# M55M1 register map
File version: 1.0
Registers are 32-bit, read-write, reset 0x0 unless marked. A register's access mark holds for its fields unless they carry their own. Offsets are from the block's base; [hi:lo] are bit positions; {n}, {i} and the like mark numbered series.

## LPUART0 — LPUART Register Map
Base 0x40446000
Same registers: LPUART0_NS 0x50446000
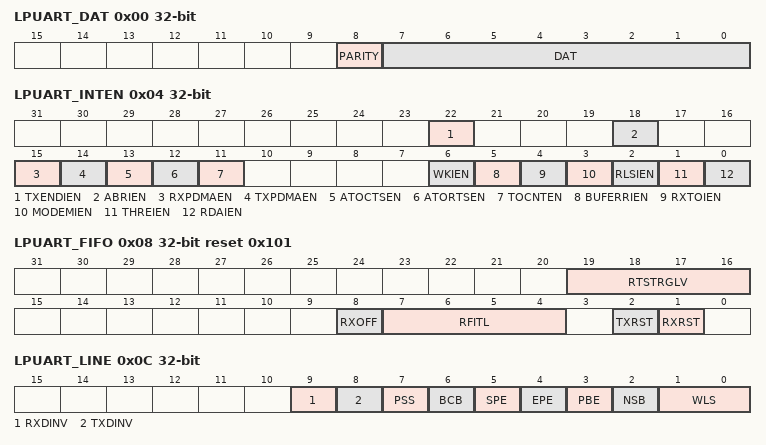
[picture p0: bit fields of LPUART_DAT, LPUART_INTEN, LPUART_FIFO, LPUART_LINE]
0x00 LPUART_DAT reset not defined — LPUART Receive/Transmit Buffer Register
  [8] PARITY — PARITY Bit Receive/Transmit Buffer. Write Operation: By writing to this bit, the PARITY bit will be stored in transmitter FIFO. If PBE (LPUART_LINE[3]) and PSS (LPUART_LINE[7]) are set, the LPUART controller will send out this bit follow the DAT (LPUART_DAT[7:0]) through the LPUART_TXD. Read Operation: If PBE (LPUART_LINE[3]) and PSS (LPUART_LINE[7]) are enabled, the PARITY bit can be read by this bit. Note: This bit has effect only when PBE (LPUART_LINE[3]) and PSS (LPUART_LINE[7]) are set.
  [7:0] DAT — Data Receive/Transmit Buffer. Write Operation: By writing one byte to this register, the data byte will be stored in transmitter FIFO. The LPUART controller will send out the data stored in transmitter FIFO top location through the LPUART_TXD. Read Operation: By reading this register, the LPUART controller will return an 8-bit data received from receiver FIFO.
0x04 LPUART_INTEN — LPUART Interrupt Enable Register
  [22] TXENDIEN — Transmitter Empty Interrupt Enable Bit. If TXENDIEN (LPUART_INTEN[22]) is enabled, the Transmitter Empty interrupt TXENDINT (LPUART_INTSTS[30]) will be generated when TXENDIF (LPUART_INTSTS[22]) is set (TX FIFO (LPUART_DAT) is empty and the STOP bit of the last byte has been transmitted).
    0=Transmitter empty interrupt Disabled; 1=Transmitter empty interrupt Enabled
  [18] ABRIEN — Auto-baud Rate Interrupt Enable Bit
    0=Auto-baud rate interrupt Disabled; 1=Auto-baud rate interrupt Enabled
  [15] RXPDMAEN — RX LPPDMA Enable Bit. This bit can enable or disable RX LPPDMA service. Note: If RLSIEN (LPUART_INTEN[2]) is enabled and HWRLSINT (LPUART_INTSTS[26]) is set to 1, the RLS (Receive Line Status) Interrupt is caused. If RLS interrupt is caused by Break Error Flag BIF(LPUART_FIFOSTS[6]), Frame Error Flag FEF(LPUART_FIFO[5]) or Parity Error Flag PEF(LPUART_FIFOSTS[4]), LPUART LPPDMA receive request operation is stopped. Clear Break Error Flag BIF or Frame Error Flag FEF or Parity Error Flag PEF by writing '1' to corresponding BIF, FEF and PEF to make LPUART LPPDMA receive request operation continue.
    0=RX LPPDMA Disabled; 1=RX LPPDMA Enabled
  [14] TXPDMAEN — TX LPPDMA Enable Bit. Note: If RLSIEN (LPUART_INTEN[2]) is enabled and HWRLSINT (LPUART_INTSTS[26]) is set to 1, the RLS (Receive Line Status) Interrupt is caused. If RLS interrupt is caused by Break Error Flag BIF(LPUART_FIFOSTS[6]), Frame Error Flag FEF(LPUART_FIFO[5]) or Parity Error Flag PEF(LPUART_FIFOSTS[4]), LPUART LPPDMA transmit request operation is stopped. Clear Break Error Flag BIF or Frame Error Flag FEF or Parity Error Flag PEF by writing '1' to corresponding BIF, FEF and PEF to make LPUART LPPDMA transmit request operation continue.
    0=TX LPPDMA Disabled; 1=TX LPPDMA Enabled
  [13] ATOCTSEN — nCTS Auto-flow Control Enable Bit. Note: When nCTS auto-flow is enabled, the LPUART will send data to external device if nCTS input assert (LPUART will not send data to device until nCTS is asserted).
    0=nCTS auto-flow control Disabled; 1=nCTS auto-flow control Enabled
  [12] ATORTSEN — nRTS Auto-flow Control Enable Bit. Note: When nRTS auto-flow is enabled, if the number of bytes in the RX FIFO equals the RTSTRGLV (LPUART_FIFO[19:16]), the LPUART will de-assert nRTS signal.
    0=nRTS auto-flow control Disabled; 1=nRTS auto-flow control Enabled
  [11] TOCNTEN — Receive Buffer Time-out Counter Enable Bit
    0=Receive Buffer Time-out counter Disabled; 1=Receive Buffer Time-out counter Enabled
  [6] WKIEN — Wake-up Interrupt Enable Bit
    0=Wake-up Interrupt Disabled; 1=Wake-up Interrupt Enabled
  [5] BUFERRIEN — Buffer Error Interrupt Enable Bit
    0=Buffer error interrupt Disabled; 1=Buffer error interrupt Enabled
  [4] RXTOIEN — RX Time-out Interrupt Enable Bit
    0=RX time-out interrupt Disabled; 1=RX time-out interrupt Enabled
  [3] MODEMIEN — Modem Status Interrupt Enable Bit
    0=Modem status interrupt Disabled; 1=Modem status interrupt Enabled
  [2] RLSIEN — Receive Line Status Interrupt Enable Bit
    0=Receive Line Status interrupt Disabled; 1=Receive Line Status interrupt Enabled
  [1] THREIEN — Transmit Holding Register Empty Interrupt Enable Bit
    0=Transmit holding register empty interrupt Disabled; 1=Transmit holding register empty interrupt Enabled
  [0] RDAIEN — Receive Data Available Interrupt Enable Bit
    0=Receive data available interrupt Disabled; 1=Receive data available interrupt Enabled
0x08 LPUART_FIFO reset 0x101 — LPUART FIFO Control Register
  [19:16] RTSTRGLV — nRTS Trigger Level for Auto-flow Control. Note: This field is used for auto nRTS flow control.
    0=nRTS Trigger Level is 1 byte; 1=nRTS Trigger Level is 4 bytes; 2=nRTS Trigger Level is 8 bytes; 3=nRTS Trigger Level is 14 bytes
  [8] RXOFF — Receiver Disable Bit. The receiver is disabled or not (set 1 to disable receiver). Note: This bit is used for RS-485 Normal Multi-drop mode. It should be programmed before RS485NMM (LPUART_ALTCTL [8]) is programmed.
    0=Receiver Enabled; 1=Receiver Disabled
  [7:4] RFITL — RX FIFO Interrupt Trigger Level. When the number of bytes in the receive FIFO equals the RFITL, the RDAIF (LPUART_INTSTS[0]) will be set (if RDAIEN (LPUART_INTEN [0]) enabled, and an interrupt will be generated).
    0=RX FIFO Interrupt Trigger Level is 1 byte; 1=RX FIFO Interrupt Trigger Level is 4 bytes; 2=RX FIFO Interrupt Trigger Level is 8 bytes; 3=RX FIFO Interrupt Trigger Level is 14 bytes
  [2] TXRST — TX Field Software Reset. When TXRST (LPUART_FIFO[2]) is set, all the byte in the transmit FIFO and TX internal state machine are cleared. Note 1: This bit will automatically clear at least 3 LPUART peripheral clock cycles. Note 2: Before setting this bit, it should wait for the TXEMPTYF (LPUART_FIFOSTS[28]) be set.
    0=No effect; 1=Reset the TX internal state machine and pointers
  [1] RXRST — RX Field Software Reset. When RXRST (LPUART_FIFO[1]) is set, all the byte in the receiver FIFO and RX internal state machine are cleared. Note 1: This bit will automatically clear at least 3 LPUART peripheral clock cycles. Note 2: Before setting this bit, it should wait for the RXIDLE (LPUART_FIFOSTS[29]) be set.
    0=No effect; 1=Reset the RX internal state machine and pointers
0x0C LPUART_LINE — LPUART Line Control Register
  [9] RXDINV — RX Data Inverted. Note 1: Before setting this bit, TXRXDIS (LPUART_FUNCSEL[3]) should be set then waited for TXRXACT (LPUART_FIFOSTS[31]) is cleared. When the configuration is done, cleared TXRXDIS (LPUART_FUNCSEL[3]) to activate LPUART controller. Note 2: This bit is valid when FUNCSEL (LPUART_FUNCSEL[2:0]) is select LPUART or RS485 function.
    0=Received data signal inverted Disabled; 1=Received data signal inverted Enabled
  [8] TXDINV — TX Data Inverted. Note 1: Before setting this bit, TXRXDIS (LPUART_FUNCSEL[3]) should be set then waited for TXRXACT (LPUART_FIFOSTS[31]) is cleared. When the configuration is done, cleared TXRXDIS (LPUART_FUNCSEL[3]) to activate LPUART controller. Note 2: This bit is valid when FUNCSEL (LPUART_FUNCSEL[2:0]) is select LPUART or RS485 function.
    0=Transmitted data signal inverted Disabled; 1=Transmitted data signal inverted Enabled
  [7] PSS — PARITY Bit Source Selection. The PARITY bit can be selected to be generated and checked automatically or by software. Note 1: This bit has effect only when PBE (LPUART_LINE[3]) is set. Note 2: If PSS is 0, the PARITY bit is transmitted and checked automatically. If PSS is 1, the transmitted PARITY bit value can be determined by writing PARITY (LPUART_DAT[8]) and the PARITY bit can be read by reading PARITY (LPUART_DAT[8]).
    0=PARITY bit is generated by EPE (LPUART_LINE[4]) and SPE (LPUART_LINE[5]) setting and checked automatically; 1=PARITY bit generated and checked by software
  [6] BCB — Break Control Bit. Note: When this bit is set to logic 1, the transmitted serial data output (TX) is forced to the Spacing State (logic 0). This bit acts only on TX line and has no effect on the transmitter logic.
    0=Break Control Disabled; 1=Break Control Enabled
  [5] SPE — Stick Parity Enable Bit. Note: If PBE (LPUART_LINE[3]) and EPE (LPUART_LINE[4]) are logic 1, the PARITY bit is transmitted and checked as logic 0. If PBE (LPUART_LINE[3]) is 1 and EPE (LPUART_LINE[4]) is 0 then the PARITY bit is transmitted and checked as 1.
    0=Stick parity Disabled; 1=Stick parity Enabled
  [4] EPE — Even Parity Enable Bit. Note: This bit has effect only when PBE (LPUART_LINE[3]) is set.
    0=Odd number of logic 1's is transmitted and checked in each word; 1=Even number of logic 1's is transmitted and checked in each word
  [3] PBE — PARITY Bit Enable Bit. Note: PARITY bit is generated on each outgoing character and is checked on each incoming data.
    0=PARITY bit generated Disabled; 1=PARITY bit generated Enabled
  [2] NSB — Number of 'STOP Bit'
    0=One 'STOP bit' is generated in the transmitted data; 1=When select 5-bit word length, 1.5 'STOP bit' is generated in the transmitted data. When select 6-, 7- and 8-bit word length, 2 'STOP bit' is generated in the transmitted data
  [1:0] WLS — Word Length Selection. This field sets LPUART word length.
    {v}={v+5} bits (v=0..3)
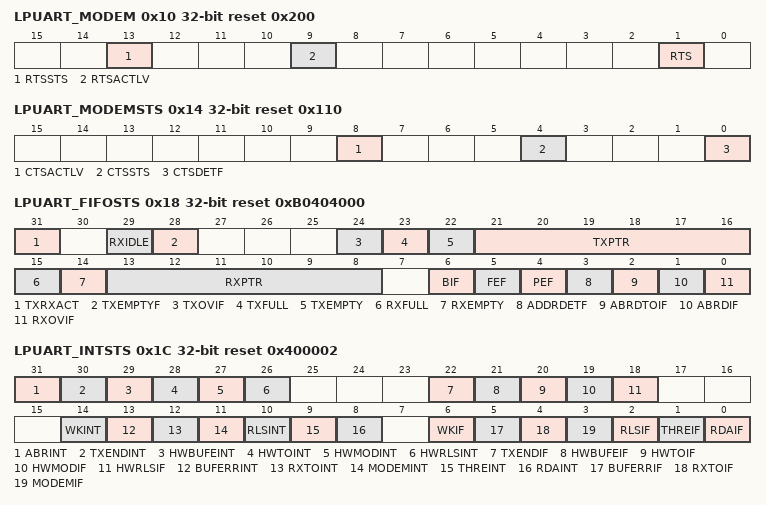
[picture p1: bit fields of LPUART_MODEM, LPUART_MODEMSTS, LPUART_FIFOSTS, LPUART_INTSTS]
0x10 LPUART_MODEM reset 0x200 — LPUART Modem Control Register
  [13] RTSSTS ro — nRTS Pin Status (Read Only). This bit mirror from nRTS pin output of voltage logic status.
    0=nRTS pin output is low level voltage logic state; 1=nRTS pin output is high level voltage logic state
  [9] RTSACTLV — nRTS Pin Active Level. This bit defines the active level state of nRTS pin output. Note 1: Refer to Figure 6.2613 and Figure 6.2614 for LPUART function mode. Note 2: Refer to Figure 6.2624 and Figure 6.2625 for RS-485 function mode. Note 3: Before setting this bit, TXRXDIS (LPUART_FUNCSEL[3]) should be set then waited for TXRXACT (LPUART_FIFOSTS[31]) is cleared. When the configuration is done, cleared TXRXDIS (LPUART_FUNCSEL[3]) to activate LPUART controller.
    0=nRTS pin output is high level active; 1=nRTS pin output is low level active. (Default)
  [1] RTS — nRTS Signal Control. This bit is direct control internal nRTS (Request-to-send) signal active or not, and then drive the nRTS pin output with RTSACTLV bit configuration. Note 1: The nRTS signal control bit is not effective when nRTS auto-flow control is enabled in LPUART function mode. Note 2: The nRTS signal control bit is not effective when RS-485 auto direction mode (AUD) is enabled in RS-485 function mode.
    0=nRTS signal is active; 1=nRTS signal is inactive
0x14 LPUART_MODEMSTS reset 0x110 — LPUART Modem Status Register
  [8] CTSACTLV — nCTS Pin Active Level. This bit defines the active level state of nCTS pin input. Note: Before setting this bit, TXRXDIS (LPUART_FUNCSEL[3]) should be set then waited for TXRXACT (LPUART_FIFOSTS[31]) is cleared. When the configuration is done, cleared TXRXDIS (LPUART_FUNCSEL[3]) to activate LPUART controller.
    0=nCTS pin input is high level active; 1=nCTS pin input is low level active. (Default)
  [4] CTSSTS ro — nCTS Pin Status (Read Only). This bit mirror from nCTS pin input of voltage logic status. Note: This bit echoes when LPUART controller peripheral clock is enabled, and nCTS multi-function port is selected.
    0=nCTS pin input is low level voltage logic state; 1=nCTS pin input is high level voltage logic state
  [0] CTSDETF — Detect nCTS State Change Flag. This bit is set whenever nCTS input has change state, and it will generate Modem interrupt to CPU when MODEMIEN (LPUART_INTEN [3]) is set to 1. Note: This bit can be cleared by writing '1' to it.
    0=nCTS input has not change state; 1=nCTS input has change state
0x18 LPUART_FIFOSTS reset 0xB0404000 — LPUART FIFO Status Register
  [31] TXRXACT ro — TX and RX Active Status (Read Only). This bit indicates TX and RX are active or inactive. Note: When TXRXDIS (LPUART_FUNCSEL[3]) is set and both TX and RX are in idle state, this bit is cleared. The LPUART controller cannot transmit or receive data at this moment. Otherwise this bit is set.
    0=TX and RX are inactive; 1=TX and RX are active. (Default)
  [29] RXIDLE ro — RX Idle Status (Read Only). This bit is set by hardware when RX is idle.
    0=RX is busy; 1=RX is idle. (Default)
  [28] TXEMPTYF ro — Transmitter Empty Flag (Read Only). This bit is set by hardware when TX FIFO (LPUART_DAT) is empty and the STOP bit of the last byte has been transmitted. Note: This bit is cleared automatically when TX FIFO is not empty or the last byte transmission has not completed.
    0=TX FIFO is not empty or the STOP bit of the last byte has been not transmitted; 1=TX FIFO is empty and the STOP bit of the last byte has been transmitted
  [24] TXOVIF — TX Overflow Error Interrupt Flag. If TX FIFO (LPUART_DAT) is full, an additional write to LPUART_DAT will cause this bit to logic 1. Note: This bit can be cleared by writing '1' to it.
    0=TX FIFO is not overflow; 1=TX FIFO is overflow
  [23] TXFULL ro — Transmitter FIFO Full (Read Only). This bit indicates TX FIFO full or not. Note: This bit is set when the number of usage in TX FIFO Buffer is equal to 16, otherwise it is cleared by hardware.
    0=TX FIFO is not full; 1=TX FIFO is full
  [22] TXEMPTY ro — Transmitter FIFO Empty (Read Only). This bit indicates TX FIFO empty or not. Note: When the last byte of TX FIFO has been transferred to Transmitter Shift Register, hardware sets this bit high. It will be cleared when writing data into LPUART_DAT (TX FIFO not empty).
    0=TX FIFO is not empty; 1=TX FIFO is empty
  [21:16] TXPTR ro — TX FIFO Pointer (Read Only). This field indicates the TX FIFO Buffer Pointer. When CPU writes one byte into LPUART_DAT, TXPTR increases one. When one byte of TX FIFO is transferred to Transmitter Shift Register, TXPTR decreases one. The Maximum value shown in TXPTR is 15. When the using level of TX FIFO Buffer equal to 16, the TXFULL bit is set to 1 and TXPTR will show 0. As one byte of TX FIFO is transferred to Transmitter Shift Register, the TXFULL bit is cleared to 0 and TXPTR will show 15.
  [15] RXFULL ro — Receiver FIFO Full (Read Only). This bit initiates RX FIFO full or not. Note: This bit is set when the number of usage in RX FIFO Buffer is equal to 16, otherwise it is cleared by hardware.
    0=RX FIFO is not full; 1=RX FIFO is full
  [14] RXEMPTY ro — Receiver FIFO Empty (Read Only). This bit initiate RX FIFO empty or not. Note: When the last byte of RX FIFO has been read by CPU, hardware sets this bit high. It will be cleared when LPUART receives any new data.
    0=RX FIFO is not empty; 1=RX FIFO is empty
  [13:8] RXPTR ro — RX FIFO Pointer (Read Only). This field indicates the RX FIFO Buffer Pointer. When LPUART receives one byte from external device, RXPTR increases one. When one byte of RX FIFO is read by CPU, RXPTR decreases one. The Maximum value shown in RXPTR is 15. When the using level of RX FIFO Buffer equal to 16, the RXFULL bit is set to 1 and RXPTR will show 0. As one byte of RX FIFO is read by CPU, the RXFULL bit is cleared to 0 and RXPTR will show 15.
  [6] BIF — Break Interrupt Flag. This bit is set to logic 1 whenever the received data input (RX) is held in the 'spacing state' (logic 0) for longer than a full word transmission time (that is, the total time of 'START bit' + data bits + parity + STOP bits). Note: This bit can be cleared by writing '1' to it.
    0=No Break interrupt is generated; 1=Break interrupt is generated
  [5] FEF — Framing Error Flag. This bit is set to logic 1 whenever the received character does not have a valid 'STOP bit' (that is, the STOP bit following the last data bit or PARITY bit is detected as logic 0). Note: This bit can be cleared by writing '1' to it.
    0=No framing error is generated; 1=Framing error is generated
  [4] PEF — Parity Error Flag. This bit is set to logic 1 whenever the received character does not have a valid 'PARITY bit'. Note: This bit can be cleared by writing '1' to it.
    0=No parity error is generated; 1=Parity error is generated
  [3] ADDRDETF — RS-485 Address Byte Detect Flag. Note 1: This field is used for RS-485 function mode and ADDRDEN (LPUART_ALTCTL[15]) is set to 1 to enable Address detection mode. Note 2: This bit can be cleared by writing '1' to it.
    0=Receiver detects a data that is not an address bit (bit 9 ='0'); 1=Receiver detects a data that is an address bit (bit 9 ='1')
  [2] ABRDTOIF — Auto-baud Rate Detect Time-out Interrupt Flag. This bit is set to logic '1' in Auto-baud Rate Detect mode when the baud rate counter is overflow. Note: This bit can be cleared by writing '1' to it.
    0=Auto-baud rate counter is underflow; 1=Auto-baud rate counter is overflow
  [1] ABRDIF — Auto-baud Rate Detect Interrupt Flag. This bit is set to logic '1' when auto-baud rate detect function is finished. Note: This bit can be cleared by writing '1' to it.
    0=Auto-baud rate detect function is not finished; 1=Auto-baud rate detect function is finished
  [0] RXOVIF — RX Overflow Error Interrupt Flag. This bit is set when RX FIFO overflow. If the number of bytes of received data is greater than RX_FIFO (LPUART_DAT) size 16 bytes, this bit will be set. Note: This bit can be cleared by writing '1' to it.
    0=RX FIFO is not overflow; 1=RX FIFO is overflow
0x1C LPUART_INTSTS reset 0x400002 — LPUART Interrupt Status Register
  [31] ABRINT ro — Auto-baud Rate Interrupt Indicator (Read Only). This bit is set if ABRIEN (LPUART_INTEN[18]) and ABRIF (LPUART_ALTCTL[17]) are both set to 1.
    0=No Auto-baud Rate interrupt is generated; 1=The Auto-baud Rate interrupt is generated
  [30] TXENDINT ro — Transmitter Empty Interrupt Indicator (Read Only). This bit is set if TXENDIEN (LPUART_INTEN[22]) and TXENDIF(LPUART_INTSTS[22]) are both set to 1.
    0=No Transmitter Empty interrupt is generated; 1=Transmitter Empty interrupt is generated
  [29] HWBUFEINT ro — LPPDMA Mode Buffer Error Interrupt Indicator (Read Only). This bit is set if BUFERRIEN (LPUART_INTEN[5]) and HWBUFEIF (LPUART_INTSTS[21]) are both set to 1.
    0=No buffer error interrupt is generated in LPPDMA mode; 1=Buffer error interrupt is generated in LPPDMA mode
  [28] HWTOINT ro — LPPDMA Mode RX Time-out Interrupt Indicator (Read Only). This bit is set if RXTOIEN (LPUART_INTEN[4]) and HWTOIF(LPUART_INTSTS[20]) are both set to 1.
    0=No RX time-out interrupt is generated in LPPDMA mode; 1=RX time-out interrupt is generated in LPPDMA mode
  [27] HWMODINT ro — LPPDMA Mode MODEM Status Interrupt Indicator (Read Only). This bit is set if MODEMIEN (LPUART_INTEN[3]) and HWMODIF(LPUART_INTSTS[19]) are both set to 1.
    0=No Modem interrupt is generated in LPPDMA mode; 1=Modem interrupt is generated in LPPDMA mode
  [26] HWRLSINT ro — LPPDMA Mode Receive Line Status Interrupt Indicator (Read Only). This bit is set if RLSIEN (LPUART_INTEN[2]) and HWRLSIF(LPUART_INTSTS[18]) are both set to 1.
    0=No RLS interrupt is generated in LPPDMA mode; 1=RLS interrupt is generated in LPPDMA mode
  [22] TXENDIF — Transmitter Empty Interrupt Flag. This bit is set when TX FIFO (LPUART_DAT) is empty and the STOP bit of the last byte has been transmitted (TXEMPTYF (LPUART_FIFOSTS[28]) is set). If TXENDIEN (LPUART_INTEN[22]) is enabled, the Transmitter Empty interrupt will be generated. Note: This bit is cleared automatically when TX FIFO is not empty or the last byte transmission has not completed.
    0=No transmitter empty interrupt flag is generated; 1=Transmitter empty interrupt flag is generated
  [21] HWBUFEIF ro — LPPDMA Mode Buffer Error Interrupt Flag (Read Only). This bit is set when the TX or RX FIFO overflows (TXOVIF (LPUART_FIFOSTS [24]) or RXOVIF (LPUART_FIFOSTS[0]) is set). When BUFERRIF (LPUART_INTSTS[5]) is set, the transfer maybe is not correct. If BUFERRIEN (LPUART_INTEN [5]) is enabled, the buffer error interrupt will be generated. Note: This bit is cleared when both TXOVIF (LPUART_FIFOSTS[24]]) and RXOVIF (LPUART_FIFOSTS[0]) are cleared.
    0=No buffer error interrupt flag is generated in LPPDMA mode; 1=Buffer error interrupt flag is generated in LPPDMA mode
  [20] HWTOIF — LPPDMA Mode RX Time-out Interrupt Flag. This bit is set when the RX FIFO is not empty and no activities occurred in the RX FIFO and the time-out counter equal to TOIC (LPUART_TOUT[7:0]). If RXTOIEN (LPUART_INTEN [4]) is enabled, the RX time-out interrupt will be generated. Note: This bit can be cleared by writing '1' to it. When BITOMEN (LPUART_TOUT[31]) is reset, this bit can also be cleared by reading LPUART_DAT.
    0=No RX time-out interrupt flag is generated in LPPDMA mode; 1=RX time-out interrupt flag is generated in LPPDMA mode
  [19] HWMODIF ro — LPPDMA Mode MODEM Interrupt Flag (Read Only). Note: This bit is read only and reset to 0 when the bit CTSDETF (LPUART_MODEMSTS[0]) is cleared by writing 1 on CTSDETF (LPUART_MODEMSTS [0]).
    0=No Modem interrupt flag is generated in LPPDMA mode; 1=Modem interrupt flag is generated in LPPDMA mode
  [18] HWRLSIF ro — LPPDMA Mode Receive Line Status Flag (Read Only). This bit is set when the RX receive data have parity error, frame error or break error (at least one of 3 bits, BIF (LPUART_FIFOSTS[6]), FEF (LPUART_FIFOSTS[5]) and PEF (LPUART_FIFOSTS[4]) is set). If RLSIEN (LPUART_INTEN [2]) is enabled, the RLS interrupt will be generated. Note 2: In LPUART function mode, this bit is read only and reset to 0 when all bits of BIF(LPUART_FIFOSTS[6]), FEF(LPUART_FIFOSTS[5]) and PEF(LPUART_FIFOSTS[4]) are cleared. Note 3: In RS-485 function mode, this bit is read only and reset to 0 when all bits of BIF(LPUART_FIFOSTS[6]), FEF(LPUART_FIFOSTS[5]), PEF(LPUART_FIFOSTS[4]) and ADDRDETF (LPUART_FIFOSTS[3]) are cleared.
    0=No RLS interrupt flag is generated in LPPDMA mode; 1=RLS interrupt flag is generated in LPPDMA mode
  [14] WKINT ro — LPUART Wake-up Interrupt Indicator (Read Only). This bit is set if WKIEN (LPUART_INTEN[6]) and WKIF (LPUART_INTSTS[6]) are both set to 1.
    0=No LPUART wake-up interrupt is generated; 1=LPUART wake-up interrupt is generated
  [13] BUFERRINT ro — Buffer Error Interrupt Indicator (Read Only). This bit is set if BUFERRIEN(LPUART_INTEN[5]) and BUFERRIF(LPUART_ INTSTS[5]) are both set to 1.
    0=No buffer error interrupt is generated; 1=Buffer error interrupt is generated
  [12] RXTOINT ro — RX Time-out Interrupt Indicator (Read Only). This bit is set if RXTOIEN (LPUART_INTEN[4]) and RXTOIF(LPUART_INTSTS[4]) are both set to 1.
    0=No RX time-out interrupt is generated; 1=RX time-out interrupt is generated
  [11] MODEMINT ro — MODEM Status Interrupt Indicator (Read Only). This bit is set if MODEMIEN(LPUART_INTEN[3]) and MODEMIF(LPUART_INTSTS[3]) are both set to 1
    0=No Modem interrupt is generated; 1=Modem interrupt is generated
  [10] RLSINT ro — Receive Line Status Interrupt Indicator (Read Only). This bit is set if RLSIEN (LPUART_INTEN[2]) and RLSIF(LPUART_INTSTS[2]) are both set to 1.
    0=No RLS interrupt is generated; 1=RLS interrupt is generated
  [9] THREINT ro — Transmit Holding Register Empty Interrupt Indicator (Read Only). This bit is set if THREIEN (LPUART_INTEN[1]) and THREIF(LPUART_INTSTS[1]) are both set to 1.
    0=No THRE interrupt is generated; 1=THRE interrupt is generated
  [8] RDAINT ro — Receive Data Available Interrupt Indicator (Read Only). This bit is set if RDAIEN (LPUART_INTEN[0]) and RDAIF (LPUART_INTSTS[0]) are both set to 1.
    0=No RDA interrupt is generated; 1=RDA interrupt is generated
  [6] WKIF ro — LPUART Wake-up Interrupt Flag (Read Only). This bit is set when TOUTWKF (LPUART_WKSTS[4]), RS485WKF (LPUART_WKSTS[3]), RFRTWKF (LPUART_WKSTS[2]), DATWKF (LPUART_WKSTS[1]) or CTSWKF(LPUART_WKSTS[0]) is set to 1. Note: This bit is cleared if all of TOUTWKF, RS485WKF, RFRTWKF, DATWKF and CTSWKF are cleared to 0 by writing 1 to the corresponding interrupt flag.
    0=No LPUART wake-up interrupt flag is generated; 1=LPUART wake-up interrupt flag is generated
  [5] BUFERRIF ro — Buffer Error Interrupt Flag (Read Only). This bit is set when the TX FIFO or RX FIFO overflows (TXOVIF (LPUART_FIFOSTS[24]) or RXOVIF (LPUART_FIFOSTS[0]) is set). When BUFERRIF (LPUART_INTSTS[5]) is set, the transfer is not correct. If BUFERRIEN (LPUART_INTEN [5]) is enabled, the buffer error interrupt will be generated. Note: This bit is cleared if both of RXOVIF(LPUART_FIFOSTS[0]) and TXOVIF(LPUART_FIFOSTS[24]) are cleared to 0 by writing 1 to RXOVIF(LPUART_FIFOSTS[0]) and TXOVIF(LPUART_FIFOSTS[24]).
    0=No buffer error interrupt flag is generated; 1=Buffer error interrupt flag is generated
  [4] RXTOIF — RX Time-out Interrupt Flag. This bit is set when the RX FIFO is not empty and no activities occurred in the RX FIFO and the time-out counter equal to TOIC (LPUART_TOUT[7:0]). If RXTOIEN (LPUART_INTEN [4]) is enabled, the RX time-out interrupt will be generated. Note: This bit can be cleared by writing '1' to it. When BITOMEN (LPUART_TOUT[31]) is reset, this bit can also be cleared by reading LPUART_DAT.
    0=No RX time-out interrupt flag is generated; 1=RX time-out interrupt flag is generated
  [3] MODEMIF ro — MODEM Interrupt Flag (Read Only). Note: This bit is read only and reset to 0 when bit CTSDETF is cleared by a write 1 on CTSDETF(LPUART_MODEMSTS[0]).
    0=No Modem interrupt flag is generated; 1=Modem interrupt flag is generated
  [2] RLSIF ro — Receive Line Interrupt Flag (Read Only). This bit is set when the RX receive data have parity error, frame error or break error (at least one of 3 bits, BIF(LPUART_FIFOSTS[6]), FEF(LPUART_FIFOSTS[5]) and PEF(LPUART_FIFOSTS[4]), is set). If RLSIEN (LPUART_INTEN [2]) is enabled, the RLS interrupt will be generated. Note 2: This bit is read only and reset to 0 when all bits of BIF (LPUART_FIFOSTS[6]), FEF(LPUART_FIFOSTS[5]) and PEF(LPUART_FIFOSTS[4]) are cleared. Note 3: In RS-485 function mode, this bit is read only and reset to 0 when all bits of BIF (LPUART_FIFOSTS[6]), FEF(LPUART_FIFOSTS[5]), PEF(LPUART_FIFOSTS[4]) and ADDRDETF (LPUART_FIFOSTS[3]) are cleared.
    0=No RLS interrupt flag is generated; 1=RLS interrupt flag is generated
  [1] THREIF ro — Transmit Holding Register Empty Interrupt Flag (Read Only). This bit is set when the last data of TX FIFO is transferred to Transmitter Shift Register. If THREIEN (LPUART_INTEN[1]) is enabled, the THRE interrupt will be generated. Note: This bit is read only and will be cleared when writing data into LPUART_DAT (TX FIFO is not empty).
    0=No THRE interrupt flag is generated; 1=THRE interrupt flag is generated
  [0] RDAIF ro — Receive Data Available Interrupt Flag (Read Only). When the number of bytes in the RX FIFO equals the RFITL then the RDAIF(LPUART_INTSTS[0]) will be set. If RDAIEN (LPUART_INTEN [0]) is enabled, the RDA interrupt will be generated. Note: This bit is read only and will be cleared when the number of unread bytes of RX FIFO drops below the threshold level (RFITL(LPUART_FIFO[7:4]).
    0=No RDA interrupt flag is generated; 1=RDA interrupt flag is generated
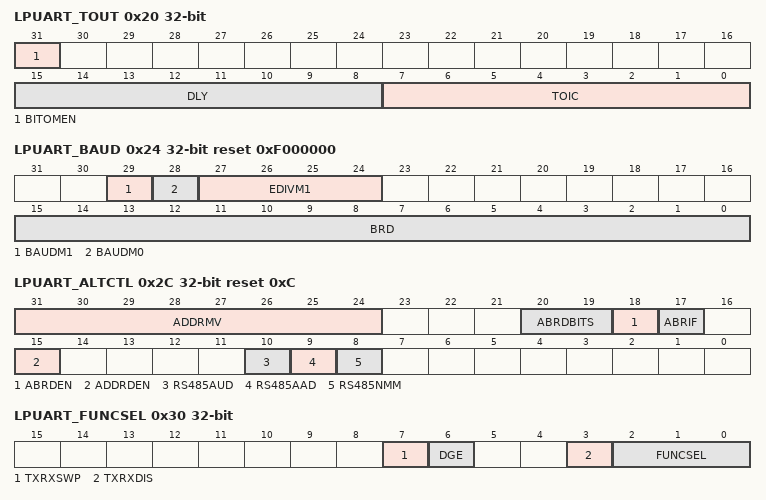
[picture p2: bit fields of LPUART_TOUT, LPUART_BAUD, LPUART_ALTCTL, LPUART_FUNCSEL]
0x20 LPUART_TOUT — LPUART Time-out Register
  [31] BITOMEN — Bus Idle Time-out Mode Enable Bit. If BITOMEN (LPUART_TOUT[31]) is enabled, the reset conditions of the time-out counter and RXTOIF (LPUART_INTSTS[4]) will be changed to detect the bus idle. When BITOMEN (LPUART_TOUT[31]) is disabled, the time-out counter and RXTOIF (LPUART_INTSTS[4]) maintain reset value whenever the RX FIFO is empty. In addition, a new incoming data word will also clear RXTOIF (LPUART_INTSTS[4]). On the other hand, when BITOMEN (LPUART_TOUT[31]) is enabled, the RX FIFO empty state will not reset the time-out counter and RXTOIF (LPUART_INTSTS[4]), and the new incoming data word event will not clear RXTOIF (LPUART_INTSTS[4]).
    0=Bus idle time-out mode Disabled; 1=Bus idle time-out mode Enabled
  [15:8] DLY — TX Delay Time Value. This field is used to program the transfer delay time between the last STOP bit and next START bit. The unit is bit time.
  [7:0] TOIC — Time-out Interrupt Comparator
0x24 LPUART_BAUD reset 0xF000000 — LPUART Baud Rate Divider Register
  [29] BAUDM1 — BAUD Rate Mode Selection Bit 1. This bit is baud rate mode selection bit 1. LPUART provides three baud rate calculation modes. This bit combines with BAUDM0 (LPUART_BAUD[28]) to select baud rate calculation mode. The detail description is shown in Table 6.264.
  [28] BAUDM0 — BAUD Rate Mode Selection Bit 0. This bit is baud rate mode selection bit 0. LPUART provides three baud rate calculation modes. This bit combines with BAUDM1 (LPUART_BAUD[29]) to select baud rate calculation mode. The detail description is shown in Table 6.264.
  [27:24] EDIVM1 — Extra Divider for BAUD Rate Mode 1. This field is used for baud rate calculation in mode 1 and has no effect for baud rate calculation in mode 0 and mode 2. The detail description is shown in Table 6.264.
  [15:0] BRD — Baud Rate Divider. The field indicates the baud rate divider. This filed is used in baud rate calculation. The detail description is shown in Table 6.264.
0x2C LPUART_ALTCTL reset 0xC — LPUART Alternate Control/Status Register
  [31:24] ADDRMV — Address Match Value. This field contains the RS-485 address match values. Note: This field is used for RS-485 auto address detection mode.
  [20:19] ABRDBITS — Auto-baud Rate Detect Bit Length. Note : The calculation of bit number includes the START bit.
    0=1-bit time from START bit to the 1st rising edge. The input pattern shall be 0x01; 1=2-bit time from START bit to the 1st rising edge. The input pattern shall be 0x02; 2=4-bit time from START bit to the 1st rising edge. The input pattern shall be 0x08; 3=8-bit time from START bit to the 1st rising edge. The input pattern shall be 0x80
  [18] ABRDEN — Auto-baud Rate Detect Enable Bit. Note : This bit is cleared automatically after auto-baud detection is finished.
    0=Auto-baud rate detect function Disabled; 1=Auto-baud rate detect function Enabled
  [17] ABRIF ro — Auto-baud Rate Interrupt Flag (Read Only). This bit is set when auto-baud rate detection function finished or the auto-baud rate counter was overflow and if ABRIEN(LPUART_INTEN [18]) is set then the auto-baud rate interrupt will be generated. Note: This bit is read only, but it can be cleared by writing '1' to ABRDTOIF (LPUART_FIFOSTS[2]) and ABRDIF(LPUART_FIFOSTS[1]).
    0=No auto-baud rate interrupt flag is generated; 1=Auto-baud rate interrupt flag is generated
  [15] ADDRDEN — RS-485 Address Detection Enable Bit. This bit is used to enable RS-485 Address Detection mode. Note: This bit is used for RS-485 any operation mode.
    0=Address detection mode Disabled; 1=Address detection mode Enabled
  [10] RS485AUD — RS-485 Auto Direction Function. Note: It can be active with RS-485_AAD or RS-485_NMM operation mode.
    0=RS-485 Auto Direction Operation function (AUD) Disabled; 1=RS-485 Auto Direction Operation function (AUD) Enabled
  [9] RS485AAD — RS-485 Auto Address Detection Operation Mode. Note: It cannot be active with RS-485_NMM operation mode.
    0=RS-485 Auto Address Detection Operation mode (AAD) Disabled; 1=RS-485 Auto Address Detection Operation mode (AAD) Enabled
  [8] RS485NMM — RS-485 Normal Multi-drop Operation Mode. Note: It cannot be active with RS-485_AAD operation mode.
    0=RS-485 Normal Multi-drop Operation mode (NMM) Disabled; 1=RS-485 Normal Multi-drop Operation mode (NMM) Enabled
0x30 LPUART_FUNCSEL — LPUART Function Select Register
  [7] TXRXSWP — TX and RX Swap Enable Bit. Setting this bit Swaps TX pin and RX pin.
    0=TX and RX Swap Disabled; 1=TX and RX Swap Enabled
  [6] DGE — Deglitch Enable Bit. Note 1: When this bit is set to logic 1, any pulse width less than about 150 ns will be considered a glitch and will be removed in the serial data input (RX). This bit acts only on RX line and has no effect on the transmitter logic. Note 2: It is recommended to set this bit only when operating at baud rate under 2.5 Mbps.
    0=Deglitch Disabled; 1=Deglitch Enabled
  [3] TXRXDIS — TX and RX Disable Bit. Setting this bit can disable TX and RX. Note: The TX and RX will not be disabled immediately when this bit is set. The TX and RX complete current task before TX and RX are disabled. When TX and RX are disabled, the TXRXACT (LPUART_FIFOSTS[31]) is cleared.
    0=TX and RX Enabled; 1=TX and RX Disabled
  [2:0] FUNCSEL — Function Select
    0=LPUART function; 3=RS-485 function
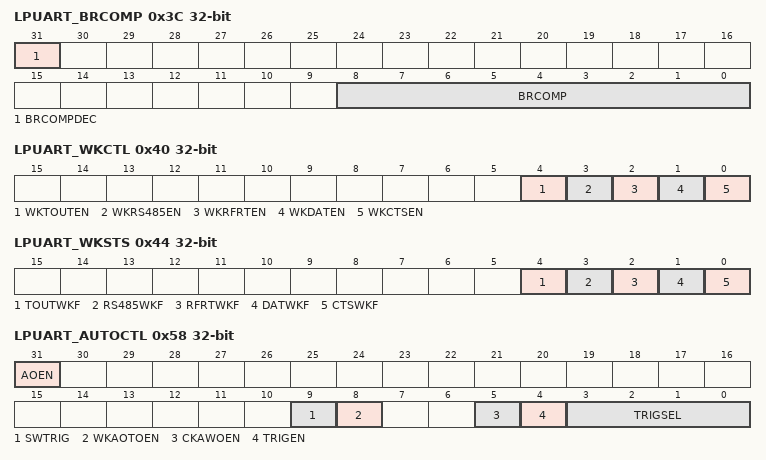
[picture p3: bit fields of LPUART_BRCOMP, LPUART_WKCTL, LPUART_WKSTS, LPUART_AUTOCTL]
0x3C LPUART_BRCOMP — LPUART Baud Rate Compensation Register
  [31] BRCOMPDEC — Baud Rate Compensation Decrease
    0=Positive (increase one module clock) compensation for each compensated bit; 1=Negative (decrease one module clock) compensation for each compensated bit
  [8:0] BRCOMP — Baud Rate Compensation Patten. These 9-bits are used to define the relative bit is compensated or not. BRCOMP[7:0] is used to define the compensation of DAT (LPUART_DAT[7:0]) and BRCOM[8] is used to define PARITY (LPUART_DAT[8]).
0x40 LPUART_WKCTL — LPUART Wake-up Control Register
  [4] WKTOUTEN — Received Data FIFO Reached Threshold Time-out Wake-up Enable Bit. Note 1: When the system is in Power-down mode, Received Data FIFO reached threshold time-out will wake up system from Power-down mode. Note 2: It is suggested the function is enabled when the WKRFRTEN (LPUART_WKCTL[2]) is set to 1.
    0=Received Data FIFO reached threshold time-out wake-up system function Disabled; 1=Received Data FIFO reached threshold time-out wake-up system function Enabled
  [3] WKRS485EN — RS-485 Address Match Wake-up Enable Bit. Note 1: When the system is in Power-down mode, RS-485 Address Match will wake-up system from Power-down mode. Note 2: This bit is used for RS-485 Auto Address Detection (AAD) mode in RS-485 function mode and ADDRDEN (LPUART_ALTCTL[15]) is set to 1.
    0=RS-485 Address Match (AAD mode) wake-up system function Disabled; 1=RS-485 Address Match (AAD mode) wake-up system function Enabled
  [2] WKRFRTEN — Received Data FIFO Reached Threshold Wake-up Enable Bit. Note: When the system is in Power-down mode, Received Data FIFO reached threshold will wake-up system from Power-down mode.
    0=Received Data FIFO reached threshold wake-up system function Disabled; 1=Received Data FIFO reached threshold wake-up system function Enabled
  [1] WKDATEN — Incoming Data Wake-up Enable Bit. Note: When the system is in Power-down mode, incoming data will wake-up system from Power-down mode.
    0=Incoming data wake-up system function Disabled; 1=Incoming data wake-up system function Enabled
  [0] WKCTSEN — nCTS Wake-up Enable Bit. Note: When the system is in Power-down mode, an external nCTS change will wake up system from Power-down mode.
    0=nCTS Wake-up system function Disabled; 1=nCTS Wake-up system function Enabled
0x44 LPUART_WKSTS — LPUART Wake-up Status Register
  [4] TOUTWKF — Received Data FIFO Threshold Time-out Wake-up Flag. This bit is set if chip wake-up from power-down state by Received Data FIFO Threshold Time-out wake-up. Note 1: If WKTOUTEN (LPUART_WKCTL[4]) is enabled, the Received Data FIFO reached threshold time-out wake-up cause this bit set to '1'. Note 2: This bit can be cleared by writing '1' to it.
    0=Chip stays in power-down state; 1=Chip wake-up from power-down state by Received Data FIFO reached threshold time-out
  [3] RS485WKF — RS-485 Address Match Wake-up Flag. This bit is set if chip wake-up from power-down state by RS-485 Address Match (AAD mode). Note 1: If WKRS485EN (LPUART_WKCTL[3]) is enabled, the RS-485 Address Match (AAD mode) wake-up cause this bit set to '1'. Note 2: This bit can be cleared by writing '1' to it.
    0=Chip stays in power-down state; 1=Chip wake-up from power-down state by RS-485 Address Match (AAD mode) wake-up
  [2] RFRTWKF — Received Data FIFO Reached Threshold Wake-up Flag. This bit is set if chip wake-up from power-down state by Received Data FIFO reached threshold wake-up. Note 1: If WKRFRTEN (LPUART_WKCTL[2]) is enabled, the Received Data FIFO Reached Threshold wake-up cause this bit set to '1'. Note 2: This bit can be cleared by writing '1' to it.
    0=Chip stays in power-down state; 1=Chip wake-up from power-down state by Received Data FIFO Reached Threshold wake-up
  [1] DATWKF — Incoming Data Wake-up Flag. This bit is set if chip wake-up from power-down state by data wake-up. Note 1: If WKDATEN (LPUART_WKCTL[1]) is enabled, the Incoming Data wake-up cause this bit set to '1'. Note 2: This bit can be cleared by writing '1' to it.
    0=Chip stays in power-down state; 1=Chip wake-up from power-down state by Incoming Data wake-up
  [0] CTSWKF — nCTS Wake-up Flag. This bit is set if chip wake-up from power-down state by nCTS wake-up. Note 1: If WKCTSEN (LPUART_WKCTL[0]) is enabled, the nCTS wake-up cause this bit set to '1'. Note 2: This bit can be cleared by writing '1' to it.
    0=Chip stays in power-down state; 1=Chip wake-up from power-down state by nCTS wake-up
0x48 LPUART_DWKCOMP — LPUART Incoming Data Wake-up Compensation Register
  [15:0] STCOMP — START Bit Compensation Value. These bits field indicate how many clock cycle selected by LPUART_CLK do the LPUART controller can get the 1st bit (START bit) when the device is wake-up from Power-down mode. Note: It is valid only when WKDATEN (LPUART_WKCTL[1]) is set.
0x4C LPUART_RS485DD — LPUART RS485 Transceiver Deactivate Delay Register
  [15:0] RTSDDLY — RS485 Transceiver Deactivate Delay Value. These bits field indicate how many clock cycles selected by LPUART_CLK do the LPUART controller delay the RS485 transceiver state trancing when the state trancing of RS485 transceiver is from TX to RX state. These bits field have no effect when the state trancing of RS485 transceiver is from RX to TX state. Note: It is valid only when RS485AUD (LPUART_ALTCTL[10]) is set.
0x58 LPUART_AUTOCTL — LPUART Automatic Operation Control Register
  [31] AOEN — Automatic Operation Enable Bit
    0=Automatic Operation Disabled; 1=Automatic Operation Enabled
  [9] SWTRIG wo — Software Trigger (Write Only). After AOEN is set to 1, software can manually trigger the automatic TX operation by writing 1 to this bit.
  [8] WKAOTOEN — Bus Idle Time-out Wake-up Enable Bit. Note 1: When the system is in Power-down mode, Bus Idle Time-out event will wake-up system from Power-down mode if WKAOTOEN (LPUART_AUTOCTL[8]), AOEN (LPUART_AUTOCTL[31]), and TOCNTEN (LPUART_INTEN[11]) are all set to '1'. Note 2: When WKAOTOEN (LPUART_AUTOCTL[8]) is reset to '0', Bus Idle Time-out Wake-up event will not wake up the system. Moreover, Bus Idle Time-out Wake-up event will gate the UART clock off if WKAOTOEN (LPUART_AUTOCTL[8]) and TRIGEN (LPUART_AUTOCTL[4]) are both reset to '0'.
    0=Bus Idle Time-out Wake-up system function Disabled; 1=Bus Idle Time-out Wake-up system function Enabled
  [5] CKAWOEN — Automatic Operation Clock Always-on Enable Bit
    0=Automatic Operation Clock Always-on Disabled; 1=Automatic Operation Clock Always-on Enabled
  [4] TRIGEN — Automatic Operation Trigger Enable Bit. When TRIGEN (LPUART_AUTOCTL[4]) is set to '1', the automatic TX operation of LPUART will be triggered by an event sent from the trigger source selected by TRIGSEL[3:0].
    0=LPUART Automatic Operation Trigger disabled; 1=LPUART Automatic Operation Trigger enabled
  [3:0] TRIGSEL — Automatic Operation Trigger Source Select
    0=Low Power Auto-operation Trigger Source from LPTMR0; 1=Low Power Auto-operation Trigger Source from LPTMR1; 2=Low Power Auto-operation Trigger Source from TTMR0; 3=Low Power Auto-operation Trigger Source from TTMR1; 4=Low Power Auto-operation Trigger Source from WKIOA0; 5=Low Power Auto-operation Trigger Source from WKIOB0; 6=Low Power Auto-operation Trigger Source from WKIOC0; 7=Low Power Auto-operation Trigger Source from WKIOD0
0x5C LPUART_AUTOSTS — LPUART Automatic Operation Status Register
  [0] AOTOWKF — Bus Idle Time-out Wake-up Flag. This bit is set if chip wake-up from power-down state by Bus Idle Time-out Wake-up. Note 1: When RXPDMAEN (LPUART_INTEN[15]) or TXPDMAEN (LPUART_INTEN[14]) is enabled, this bit is the shadow bit of HWTOIF (LPUART_INTSTS[20]); user can read/clear it by reading/resetting HWTOIF (LPUART_INTSTS[20]) or AOTOWKF (LPUART_AUTOSTS[0]). Note 2: When RXPDMAEN (LPUART_INTEN[15]) and TXPDMAEN (LPUART_INTEN[14]) are both disabled, this bit is the shadow bit of RXTOIF (LPUART_INTSTS[4]); user can read/clear it by reading/resetting RXTOIF (LPUART_INTSTS[4]) or AOTOWKF (LPUART_AUTOSTS[0]). Note 3: If WKAOTOEN (LPUART_AUTOCTL[8]) is enabled, the Bus Idle Time-out Wake-up event will set this bit. Note 4: This bit can be cleared by writing '1' to it.
    0=There is no Bus Idle Time-out Wake-up event; 1=Chip wake-up from power-down state by Bus Idle Time-out Wake-up
